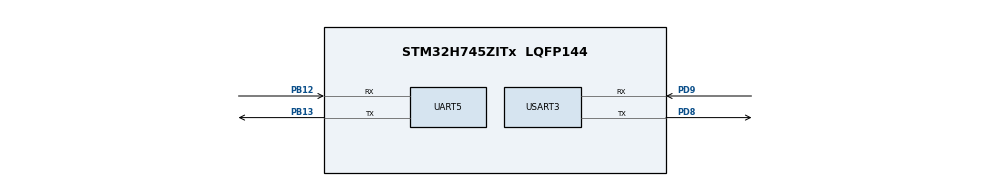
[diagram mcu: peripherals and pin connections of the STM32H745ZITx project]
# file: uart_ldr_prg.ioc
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CortexM4.IPs=BDMA,CORTEX_M4\:I,DEBUG,DMA,FATFS_M4\:I,FREERTOS_M4\:I,GPIO,IWDG2\:I,MDMA,NVIC2\:I,OPENAMP_M4\:I,PDM2PCM_M4\:I,PWR,RCC,RESMGR_UTILITY,SYS_M4\:I,USB_DEVICE_M4\:I,USB_HOST_M4\:I,VREFBUF,WWDG2\:I
CortexM7.IPs=BDMA\:I,CORTEX_M7\:I,DEBUG\:I,DMA\:I,FATFS_M7\:I,FREERTOS_M7\:I,GPIO\:I,IWDG1\:I,MDMA\:I,NVIC1\:I,OPENAMP_M7\:I,PDM2PCM_M7\:I,PWR\:I,RCC\:I,RESMGR_UTILITY\:I,SYS\:I,USB_DEVICE_M7\:I,USB_HOST_M7\:I,VREFBUF\:I,WWDG1\:I,UART5\:I,USART3\:I
Dma.Request0=UART5_RX
Dma.Request1=UART5_TX
Dma.Request2=USART3_RX
Dma.Request3=USART3_TX
Dma.UART5_RX.0.Direction=DMA_PERIPH_TO_MEMORY
Dma.UART5_RX.0.EventEnable=DISABLE
Dma.UART5_RX.0.FIFOMode=DMA_FIFOMODE_DISABLE
Dma.UART5_RX.0.Instance=DMA1_Stream2
Dma.UART5_RX.0.MemDataAlignment=DMA_MDATAALIGN_BYTE
Dma.UART5_RX.0.MemInc=DMA_MINC_ENABLE
Dma.UART5_RX.0.Mode=DMA_CIRCULAR
Dma.UART5_RX.0.PeriphDataAlignment=DMA_PDATAALIGN_BYTE
Dma.UART5_RX.0.PeriphInc=DMA_PINC_DISABLE
Dma.UART5_RX.0.Polarity=HAL_DMAMUX_REQ_GEN_RISING
Dma.UART5_RX.0.Priority=DMA_PRIORITY_LOW
Dma.UART5_RX.0.RequestNumber=1
Dma.UART5_RX.0.SignalID=NONE
Dma.UART5_RX.0.SyncEnable=DISABLE
Dma.UART5_RX.0.SyncPolarity=HAL_DMAMUX_SYNC_NO_EVENT
Dma.UART5_RX.0.SyncRequestNumber=1
Dma.UART5_RX.0.SyncSignalID=NONE
Dma.UART5_TX.1.Direction=DMA_MEMORY_TO_PERIPH
Dma.UART5_TX.1.EventEnable=DISABLE
Dma.UART5_TX.1.FIFOMode=DMA_FIFOMODE_DISABLE
Dma.UART5_TX.1.Instance=DMA1_Stream3
Dma.UART5_TX.1.MemDataAlignment=DMA_MDATAALIGN_BYTE
Dma.UART5_TX.1.MemInc=DMA_MINC_ENABLE
Dma.UART5_TX.1.Mode=DMA_CIRCULAR
Dma.UART5_TX.1.PeriphDataAlignment=DMA_PDATAALIGN_BYTE
Dma.UART5_TX.1.PeriphInc=DMA_PINC_DISABLE
Dma.UART5_TX.1.Polarity=HAL_DMAMUX_REQ_GEN_RISING
Dma.UART5_TX.1.Priority=DMA_PRIORITY_LOW
Dma.UART5_TX.1.RequestNumber=1
Dma.UART5_TX.1.SignalID=NONE
Dma.UART5_TX.1.SyncEnable=DISABLE
Dma.UART5_TX.1.SyncPolarity=HAL_DMAMUX_SYNC_NO_EVENT
Dma.UART5_TX.1.SyncRequestNumber=1
Dma.UART5_TX.1.SyncSignalID=NONE
Dma.USART3_RX.2.Direction=DMA_PERIPH_TO_MEMORY
Dma.USART3_RX.2.EventEnable=DISABLE
Dma.USART3_RX.2.FIFOMode=DMA_FIFOMODE_DISABLE
Dma.USART3_RX.2.Instance=DMA1_Stream0
Dma.USART3_RX.2.MemDataAlignment=DMA_MDATAALIGN_BYTE
Dma.USART3_RX.2.MemInc=DMA_MINC_ENABLE
Dma.USART3_RX.2.Mode=DMA_CIRCULAR
Dma.USART3_RX.2.PeriphDataAlignment=DMA_PDATAALIGN_BYTE
Dma.USART3_RX.2.PeriphInc=DMA_PINC_DISABLE
Dma.USART3_RX.2.Polarity=HAL_DMAMUX_REQ_GEN_RISING
Dma.USART3_RX.2.Priority=DMA_PRIORITY_LOW
Dma.USART3_RX.2.RequestNumber=1
Dma.USART3_RX.2.SignalID=NONE
Dma.USART3_RX.2.SyncEnable=DISABLE
Dma.USART3_RX.2.SyncPolarity=HAL_DMAMUX_SYNC_NO_EVENT
Dma.USART3_RX.2.SyncRequestNumber=1
Dma.USART3_RX.2.SyncSignalID=NONE
Dma.USART3_TX.3.Direction=DMA_MEMORY_TO_PERIPH
Dma.USART3_TX.3.EventEnable=DISABLE
Dma.USART3_TX.3.FIFOMode=DMA_FIFOMODE_DISABLE
Dma.USART3_TX.3.Instance=DMA1_Stream1
Dma.USART3_TX.3.MemDataAlignment=DMA_MDATAALIGN_BYTE
Dma.USART3_TX.3.MemInc=DMA_MINC_ENABLE
Dma.USART3_TX.3.Mode=DMA_CIRCULAR
Dma.USART3_TX.3.PeriphDataAlignment=DMA_PDATAALIGN_BYTE
Dma.USART3_TX.3.PeriphInc=DMA_PINC_DISABLE
Dma.USART3_TX.3.Polarity=HAL_DMAMUX_REQ_GEN_RISING
Dma.USART3_TX.3.Priority=DMA_PRIORITY_LOW
Dma.USART3_TX.3.RequestNumber=1
Dma.USART3_TX.3.SignalID=NONE
Dma.USART3_TX.3.SyncEnable=DISABLE
Dma.USART3_TX.3.SyncPolarity=HAL_DMAMUX_SYNC_NO_EVENT
Dma.USART3_TX.3.SyncRequestNumber=1
Dma.USART3_TX.3.SyncSignalID=NONE
Mcu.Family=STM32H7
Mcu.Name=STM32H745ZITx
Mcu.Package=LQFP144
NVIC1.DMA1_Stream0_IRQn=true\:0\:0\:false\:false\:true\:false\:true\:true
NVIC1.DMA1_Stream1_IRQn=true\:0\:0\:false\:false\:true\:false\:true\:true
NVIC1.DMA1_Stream2_IRQn=true\:0\:0\:false\:false\:true\:false\:true\:true
NVIC1.DMA1_Stream3_IRQn=true\:0\:0\:false\:false\:true\:false\:true\:true
NVIC1.PriorityGroup=NVIC_PRIORITYGROUP_4
NVIC1.UART5_IRQn=true\:0\:0\:false\:false\:true\:true\:true\:true
NVIC1.USART3_IRQn=true\:0\:0\:false\:false\:true\:true\:true\:true
NVIC2.PriorityGroup=NVIC_PRIORITYGROUP_4
PB12.Mode=Asynchronous
PB12.PinAttribute=CortexM7
PB12.Signal=UART5_RX
PB13.Mode=Asynchronous
PB13.PinAttribute=CortexM7
PB13.Signal=UART5_TX
PC14-OSC32_IN\ (OSC32_IN).Mode=LSE-External-Oscillator
PC14-OSC32_IN\ (OSC32_IN).PinAttribute=Free
PC14-OSC32_IN\ (OSC32_IN).Signal=RCC_OSC32_IN
PC15-OSC32_OUT\ (OSC32_OUT).Mode=LSE-External-Oscillator
PC15-OSC32_OUT\ (OSC32_OUT).PinAttribute=Free
PC15-OSC32_OUT\ (OSC32_OUT).Signal=RCC_OSC32_OUT
PD8.Mode=Asynchronous
PD8.PinAttribute=CortexM7
PD8.Signal=USART3_TX
PD9.Mode=Asynchronous
PD9.PinAttribute=CortexM7
PD9.Signal=USART3_RX
PH0-OSC_IN\ (PH0).Mode=HSE-External-Oscillator
PH0-OSC_IN\ (PH0).PinAttribute=Free
PH0-OSC_IN\ (PH0).Signal=RCC_OSC_IN
PH1-OSC_OUT\ (PH1).Mode=HSE-External-Oscillator
PH1-OSC_OUT\ (PH1).PinAttribute=Free
PH1-OSC_OUT\ (PH1).Signal=RCC_OSC_OUT
ProjectManager.HeapSize=M4-0x200,M7-0x200
ProjectManager.StackSize=M4-0x400,M7-0x400
ProjectManager.TargetToolchain=STM32CubeIDE
RCC.ADCFreq_Value=129000000
RCC.APB1Freq_Value=32000000
RCC.APB2Freq_Value=64000000
RCC.APB3Freq_Value=64000000
RCC.APB4Freq_Value=64000000
RCC.CortexFreq_Value=64000000
RCC.D2PPRE1=RCC_APB1_DIV2
RCC.HCLKFreq_Value=64000000
RCC.SYSCLKFreq_VALUE=64000000
RCC.USBFreq_Value=129000000
SYS.userName=SYS_M7
USART3.VirtualMode-Asynchronous=VM_ASYNC
VP_SYS_M4_VS_Systick.Mode=SysTick
board=custom

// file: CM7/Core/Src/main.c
/* USER CODE BEGIN Header */
/**
  ******************************************************************************
  * @file           : main.c
  * @brief          : Main program body
  ******************************************************************************
  * @attention
  *
  * Copyright (c) 2023 STMicroelectronics.
  * All rights reserved.
  *
  * This software is licensed under terms that can be found in the LICENSE file
  * in the root directory of this software component.
  * If no LICENSE file comes with this software, it is provided AS-IS.
  *
  ******************************************************************************
  */
/* USER CODE END Header */
#include "main.h"
#include "dma.h"
#include "usart.h"
#include "gpio.h"

/* USER CODE BEGIN Includes */
#include "lidar_reading.h"
/* USER CODE END Includes */

/* USER CODE BEGIN PD */

#ifndef HSEM_ID_0
#define HSEM_ID_0 (0U) /* HW semaphore 0*/
#endif

/* USER CODE END PD */

void SystemClock_Config(void);

int main(void)
{
/* USER CODE BEGIN Boot_Mode_Sequence_0 */
  int32_t timeout;
/* USER CODE END Boot_Mode_Sequence_0 */

/* USER CODE BEGIN Boot_Mode_Sequence_1 */
  /* Wait until CPU2 boots and enters in stop mode or timeout*/
  timeout = 0xFFFF;
  while((__HAL_RCC_GET_FLAG(RCC_FLAG_D2CKRDY) != RESET) && (timeout-- > 0));
  if ( timeout < 0 )
  {
  Error_Handler();
  }
/* USER CODE END Boot_Mode_Sequence_1 */
  /* MCU Configuration--------------------------------------------------------*/

  /* Reset of all peripherals, Initializes the Flash interface and the Systick. */
  HAL_Init();

  /* Configure the system clock */
  SystemClock_Config();
/* USER CODE BEGIN Boot_Mode_Sequence_2 */
/* When system initialization is finished, Cortex-M7 will release Cortex-M4 by means of
HSEM notification */
/*HW semaphore Clock enable*/
__HAL_RCC_HSEM_CLK_ENABLE();
/*Take HSEM */
HAL_HSEM_FastTake(HSEM_ID_0);
/*Release HSEM in order to notify the CPU2(CM4)*/
HAL_HSEM_Release(HSEM_ID_0,0);
/* wait until CPU2 wakes up from stop mode */
timeout = 0xFFFF;
while((__HAL_RCC_GET_FLAG(RCC_FLAG_D2CKRDY) == RESET) && (timeout-- > 0));
if ( timeout < 0 )
{
Error_Handler();
}
/* USER CODE END Boot_Mode_Sequence_2 */

  /* Initialize all configured peripherals */
  MX_GPIO_Init();
  MX_DMA_Init();
  MX_USART3_UART_Init();
  MX_UART5_Init();
  /* USER CODE BEGIN 2 */
  setUpLiudarDMA();
  /* USER CODE END 2 */

  /* Infinite loop */
  while (1)
  {

    /* USER CODE BEGIN 3 */
	  getTFminiData();
  }
  /* USER CODE END 3 */
}

void SystemClock_Config(void)
{
  RCC_OscInitTypeDef RCC_OscInitStruct = {0};
  RCC_ClkInitTypeDef RCC_ClkInitStruct = {0};

  /** Supply configuration update enable
  */
  HAL_PWREx_ConfigSupply(PWR_DIRECT_SMPS_SUPPLY);

  /** Configure the main internal regulator output voltage
  */
  __HAL_PWR_VOLTAGESCALING_CONFIG(PWR_REGULATOR_VOLTAGE_SCALE3);

  while(!__HAL_PWR_GET_FLAG(PWR_FLAG_VOSRDY)) {}

  /** Initializes the RCC Oscillators according to the specified parameters
  * in the RCC_OscInitTypeDef structure.
  */
  RCC_OscInitStruct.OscillatorType = RCC_OSCILLATORTYPE_HSI;
  RCC_OscInitStruct.HSIState = RCC_HSI_DIV1;
  RCC_OscInitStruct.HSICalibrationValue = RCC_HSICALIBRATION_DEFAULT;
  RCC_OscInitStruct.PLL.PLLState = RCC_PLL_NONE;
  if (HAL_RCC_OscConfig(&RCC_OscInitStruct) != HAL_OK)
  {
    Error_Handler();
  }

  /** Initializes the CPU, AHB and APB buses clocks
  */
  RCC_ClkInitStruct.ClockType = RCC_CLOCKTYPE_HCLK|RCC_CLOCKTYPE_SYSCLK
                              |RCC_CLOCKTYPE_PCLK1|RCC_CLOCKTYPE_PCLK2
                              |RCC_CLOCKTYPE_D3PCLK1|RCC_CLOCKTYPE_D1PCLK1;
  RCC_ClkInitStruct.SYSCLKSource = RCC_SYSCLKSOURCE_HSI;
  RCC_ClkInitStruct.SYSCLKDivider = RCC_SYSCLK_DIV1;
  RCC_ClkInitStruct.AHBCLKDivider = RCC_HCLK_DIV1;
  RCC_ClkInitStruct.APB3CLKDivider = RCC_APB3_DIV1;
  RCC_ClkInitStruct.APB1CLKDivider = RCC_APB1_DIV2;
  RCC_ClkInitStruct.APB2CLKDivider = RCC_APB2_DIV1;
  RCC_ClkInitStruct.APB4CLKDivider = RCC_APB4_DIV1;

  if (HAL_RCC_ClockConfig(&RCC_ClkInitStruct, FLASH_LATENCY_1) != HAL_OK)
  {
    Error_Handler();
  }
}

void Error_Handler(void)
{
  __disable_irq();
  while (1)
  {
  }
}
